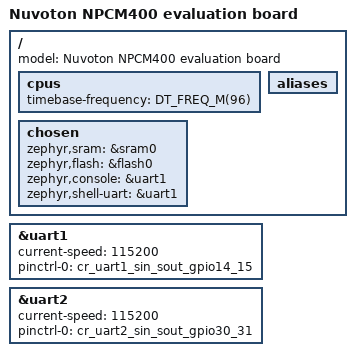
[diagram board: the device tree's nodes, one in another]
/*
 * Copyright (c) 2024 Nuvoton Technology Corporation.
 *
 * SPDX-License-Identifier: Apache-2.0
 */

/dts-v1/;

#include <nuvoton/npcm400.dtsi>
#include <nuvoton/npcm/npcm4/npcm4-pinctrl.dtsi>

/ {
	model = "Nuvoton NPCM400 evaluation board";

	cpus {
		timebase-frequency = <DT_FREQ_M(96)>;
	};

	chosen {
		zephyr,sram = &sram0;
		zephyr,flash = &flash0;
		zephyr,console = &uart1;
		zephyr,shell-uart = &uart1;
	};

	aliases {};
};

&uart1 {
	current-speed = <115200>;
	pinctrl-0 = <&cr_uart1_sin_sout_gpio14_15>;
	pinctrl-names = "default";
	status = "okay";
};

&uart2 {
	current-speed = <115200>;
	pinctrl-0 = <&cr_uart2_sin_sout_gpio30_31>;
	pinctrl-names = "default";
	status = "okay";
};
